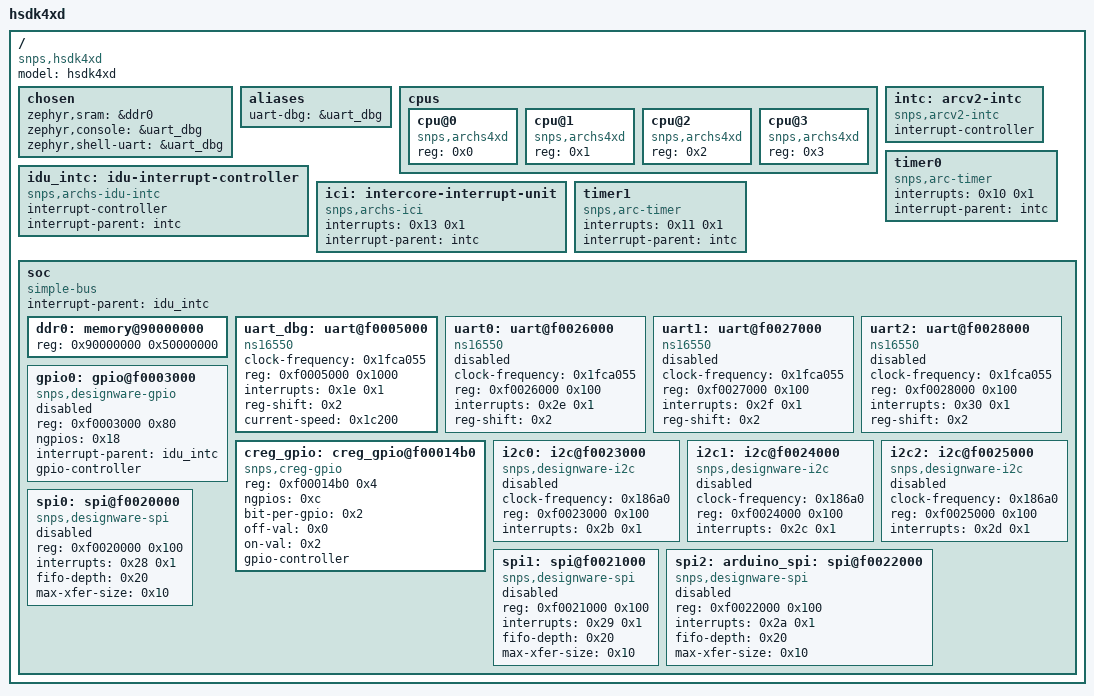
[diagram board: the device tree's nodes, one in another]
/dts-v1/;

/* node '/' defined in zephyr/dts/common/skeleton.dtsi:9 */
/ {
	#address-cells = < 0x1 >;    /* in zephyr/dts/common/skeleton.dtsi:10 */
	#size-cells = < 0x1 >;       /* in zephyr/dts/common/skeleton.dtsi:11 */
	model = "hsdk4xd";           /* in zephyr/boards/snps/hsdk4xd/hsdk4xd.dts:12 */
	compatible = "snps,hsdk4xd"; /* in zephyr/boards/snps/hsdk4xd/hsdk4xd.dts:13 */

	/* node '/chosen' defined in zephyr/dts/common/skeleton.dtsi:13 */
	chosen {
		zephyr,sram = &ddr0;           /* in zephyr/boards/snps/hsdk4xd/hsdk4xd.dts:20 */
		zephyr,console = &uart_dbg;    /* in zephyr/boards/snps/hsdk4xd/hsdk4xd.dts:21 */
		zephyr,shell-uart = &uart_dbg; /* in zephyr/boards/snps/hsdk4xd/hsdk4xd.dts:22 */
	};

	/* node '/aliases' defined in zephyr/dts/common/skeleton.dtsi:15 */
	aliases {
		uart-dbg = &uart_dbg; /* in zephyr/boards/snps/hsdk4xd/hsdk4xd.dts:16 */
	};

	/* node '/cpus' defined in zephyr/dts/arc/synopsys/arc_hs4xd.dtsi:13 */
	cpus {
		#address-cells = < 0x1 >; /* in zephyr/dts/arc/synopsys/arc_hs4xd.dtsi:14 */
		#size-cells = < 0x0 >;    /* in zephyr/dts/arc/synopsys/arc_hs4xd.dtsi:15 */

		/* node '/cpus/cpu@0' defined in zephyr/dts/arc/synopsys/arc_hs4xd.dtsi:17 */
		cpu@0 {
			device_type = "cpu";          /* in zephyr/dts/arc/synopsys/arc_hs4xd.dtsi:18 */
			compatible = "snps,archs4xd"; /* in zephyr/dts/arc/synopsys/arc_hs4xd.dtsi:19 */
			reg = < 0x0 >;                /* in zephyr/dts/arc/synopsys/arc_hs4xd.dtsi:20 */
		};

		/* node '/cpus/cpu@1' defined in zephyr/dts/arc/synopsys/arc_hs4xd.dtsi:23 */
		cpu@1 {
			device_type = "cpu";          /* in zephyr/dts/arc/synopsys/arc_hs4xd.dtsi:24 */
			compatible = "snps,archs4xd"; /* in zephyr/dts/arc/synopsys/arc_hs4xd.dtsi:25 */
			reg = < 0x1 >;                /* in zephyr/dts/arc/synopsys/arc_hs4xd.dtsi:26 */
		};

		/* node '/cpus/cpu@2' defined in zephyr/dts/arc/synopsys/arc_hs4xd.dtsi:29 */
		cpu@2 {
			device_type = "cpu";          /* in zephyr/dts/arc/synopsys/arc_hs4xd.dtsi:30 */
			compatible = "snps,archs4xd"; /* in zephyr/dts/arc/synopsys/arc_hs4xd.dtsi:31 */
			reg = < 0x2 >;                /* in zephyr/dts/arc/synopsys/arc_hs4xd.dtsi:32 */
		};

		/* node '/cpus/cpu@3' defined in zephyr/dts/arc/synopsys/arc_hs4xd.dtsi:35 */
		cpu@3 {
			device_type = "cpu";          /* in zephyr/dts/arc/synopsys/arc_hs4xd.dtsi:36 */
			compatible = "snps,archs4xd"; /* in zephyr/dts/arc/synopsys/arc_hs4xd.dtsi:37 */
			reg = < 0x3 >;                /* in zephyr/dts/arc/synopsys/arc_hs4xd.dtsi:38 */
		};
	};

	/* node '/arcv2-intc' defined in zephyr/dts/arc/synopsys/arc_hs4xd.dtsi:42 */
	intc: arcv2-intc {
		compatible = "snps,arcv2-intc"; /* in zephyr/dts/arc/synopsys/arc_hs4xd.dtsi:43 */
		interrupt-controller;           /* in zephyr/dts/arc/synopsys/arc_hs4xd.dtsi:44 */
		#interrupt-cells = < 0x2 >;     /* in zephyr/dts/arc/synopsys/arc_hs4xd.dtsi:45 */
		phandle = < 0x1 >;              /* in zephyr/dts/arc/synopsys/arc_hs4xd.dtsi:52 */
	};

	/* node '/idu-interrupt-controller' defined in zephyr/dts/arc/synopsys/arc_hs4xd.dtsi:48 */
	idu_intc: idu-interrupt-controller {
		compatible = "snps,archs-idu-intc"; /* in zephyr/dts/arc/synopsys/arc_hs4xd.dtsi:49 */
		interrupt-controller;               /* in zephyr/dts/arc/synopsys/arc_hs4xd.dtsi:50 */
		#interrupt-cells = < 0x2 >;         /* in zephyr/dts/arc/synopsys/arc_hs4xd.dtsi:51 */
		interrupt-parent = < &intc >;       /* in zephyr/dts/arc/synopsys/arc_hs4xd.dtsi:52 */
		phandle = < 0x2 >;                  /* in zephyr/dts/arc/synopsys/arc_hs4xd.dtsi:77 */
	};

	/* node '/intercore-interrupt-unit' defined in zephyr/dts/arc/synopsys/arc_hs4xd.dtsi:55 */
	ici: intercore-interrupt-unit {
		compatible = "snps,archs-ici"; /* in zephyr/dts/arc/synopsys/arc_hs4xd.dtsi:56 */
		interrupts = < 0x13 0x1 >;     /* in zephyr/dts/arc/synopsys/arc_hs4xd.dtsi:57 */
		interrupt-parent = < &intc >;  /* in zephyr/dts/arc/synopsys/arc_hs4xd.dtsi:58 */
	};

	/* node '/timer0' defined in zephyr/dts/arc/synopsys/arc_hs4xd.dtsi:61 */
	timer0: timer0 {
		compatible = "snps,arc-timer"; /* in zephyr/dts/arc/synopsys/arc_hs4xd.dtsi:62 */
		interrupts = < 0x10 0x1 >;     /* in zephyr/dts/arc/synopsys/arc_hs4xd.dtsi:63 */
		interrupt-parent = < &intc >;  /* in zephyr/dts/arc/synopsys/arc_hs4xd.dtsi:64 */
	};

	/* node '/timer1' defined in zephyr/dts/arc/synopsys/arc_hs4xd.dtsi:67 */
	timer1: timer1 {
		compatible = "snps,arc-timer"; /* in zephyr/dts/arc/synopsys/arc_hs4xd.dtsi:68 */
		interrupts = < 0x11 0x1 >;     /* in zephyr/dts/arc/synopsys/arc_hs4xd.dtsi:69 */
		interrupt-parent = < &intc >;  /* in zephyr/dts/arc/synopsys/arc_hs4xd.dtsi:70 */
	};

	/* node '/soc' defined in zephyr/dts/arc/synopsys/arc_hs4xd.dtsi:73 */
	soc {
		#address-cells = < 0x1 >;         /* in zephyr/dts/arc/synopsys/arc_hs4xd.dtsi:74 */
		#size-cells = < 0x1 >;            /* in zephyr/dts/arc/synopsys/arc_hs4xd.dtsi:75 */
		compatible = "simple-bus";        /* in zephyr/dts/arc/synopsys/arc_hs4xd.dtsi:76 */
		interrupt-parent = < &idu_intc >; /* in zephyr/dts/arc/synopsys/arc_hs4xd.dtsi:77 */
		ranges;                           /* in zephyr/dts/arc/synopsys/arc_hs4xd.dtsi:78 */

		/* node '/soc/memory@90000000' defined in zephyr/dts/arc/synopsys/arc_hs4xd.dtsi:80 */
		ddr0: memory@90000000 {
			device_type = "memory";          /* in zephyr/dts/arc/synopsys/arc_hs4xd.dtsi:81 */
			reg = < 0x90000000 0x50000000 >; /* in zephyr/dts/arc/synopsys/arc_hs4xd.dtsi:82 */
		};

		/* node '/soc/uart@f0005000' defined in zephyr/dts/arc/synopsys/arc_hs4xd.dtsi:85 */
		uart_dbg: uart@f0005000 {
			compatible = "ns16550";          /* in zephyr/dts/arc/synopsys/arc_hs4xd.dtsi:86 */
			clock-frequency = < 0x1fca055 >; /* in zephyr/dts/arc/synopsys/arc_hs4xd.dtsi:87 */
			reg = < 0xf0005000 0x1000 >;     /* in zephyr/dts/arc/synopsys/arc_hs4xd.dtsi:88 */
			interrupts = < 0x1e 0x1 >;       /* in zephyr/dts/arc/synopsys/arc_hs4xd.dtsi:89 */
			reg-shift = < 0x2 >;             /* in zephyr/dts/arc/synopsys/arc_hs4xd.dtsi:90 */
			status = "okay";                 /* in zephyr/boards/snps/hsdk4xd/hsdk4xd.dts:29 */
			current-speed = < 0x1c200 >;     /* in zephyr/boards/snps/hsdk4xd/hsdk4xd.dts:30 */
		};

		/* node '/soc/uart@f0026000' defined in zephyr/dts/arc/synopsys/arc_hs4xd.dtsi:93 */
		uart0: uart@f0026000 {
			compatible = "ns16550";          /* in zephyr/dts/arc/synopsys/arc_hs4xd.dtsi:94 */
			clock-frequency = < 0x1fca055 >; /* in zephyr/dts/arc/synopsys/arc_hs4xd.dtsi:95 */
			reg = < 0xf0026000 0x100 >;      /* in zephyr/dts/arc/synopsys/arc_hs4xd.dtsi:96 */
			interrupts = < 0x2e 0x1 >;       /* in zephyr/dts/arc/synopsys/arc_hs4xd.dtsi:97 */
			reg-shift = < 0x2 >;             /* in zephyr/dts/arc/synopsys/arc_hs4xd.dtsi:98 */
			status = "disabled";             /* in zephyr/dts/arc/synopsys/arc_hs4xd.dtsi:99 */
		};

		/* node '/soc/uart@f0027000' defined in zephyr/dts/arc/synopsys/arc_hs4xd.dtsi:102 */
		uart1: uart@f0027000 {
			compatible = "ns16550";          /* in zephyr/dts/arc/synopsys/arc_hs4xd.dtsi:103 */
			clock-frequency = < 0x1fca055 >; /* in zephyr/dts/arc/synopsys/arc_hs4xd.dtsi:104 */
			reg = < 0xf0027000 0x100 >;      /* in zephyr/dts/arc/synopsys/arc_hs4xd.dtsi:105 */
			interrupts = < 0x2f 0x1 >;       /* in zephyr/dts/arc/synopsys/arc_hs4xd.dtsi:106 */
			reg-shift = < 0x2 >;             /* in zephyr/dts/arc/synopsys/arc_hs4xd.dtsi:107 */
			status = "disabled";             /* in zephyr/dts/arc/synopsys/arc_hs4xd.dtsi:108 */
		};

		/* node '/soc/uart@f0028000' defined in zephyr/dts/arc/synopsys/arc_hs4xd.dtsi:111 */
		uart2: uart@f0028000 {
			compatible = "ns16550";          /* in zephyr/dts/arc/synopsys/arc_hs4xd.dtsi:112 */
			clock-frequency = < 0x1fca055 >; /* in zephyr/dts/arc/synopsys/arc_hs4xd.dtsi:113 */
			reg = < 0xf0028000 0x100 >;      /* in zephyr/dts/arc/synopsys/arc_hs4xd.dtsi:114 */
			interrupts = < 0x30 0x1 >;       /* in zephyr/dts/arc/synopsys/arc_hs4xd.dtsi:115 */
			reg-shift = < 0x2 >;             /* in zephyr/dts/arc/synopsys/arc_hs4xd.dtsi:116 */
			status = "disabled";             /* in zephyr/dts/arc/synopsys/arc_hs4xd.dtsi:117 */
		};

		/* node '/soc/gpio@f0003000' defined in zephyr/dts/arc/synopsys/arc_hs4xd.dtsi:120 */
		gpio0: gpio@f0003000 {
			compatible = "snps,designware-gpio"; /* in zephyr/dts/arc/synopsys/arc_hs4xd.dtsi:121 */
			reg = < 0xf0003000 0x80 >;           /* in zephyr/dts/arc/synopsys/arc_hs4xd.dtsi:122 */
			ngpios = < 0x18 >;                   /* in zephyr/dts/arc/synopsys/arc_hs4xd.dtsi:123 */
			interrupt-parent = < &idu_intc >;    /* in zephyr/dts/arc/synopsys/arc_hs4xd.dtsi:124 */
			gpio-controller;                     /* in zephyr/dts/arc/synopsys/arc_hs4xd.dtsi:126 */
			#gpio-cells = < 0x2 >;               /* in zephyr/dts/arc/synopsys/arc_hs4xd.dtsi:127 */
			status = "disabled";                 /* in zephyr/dts/arc/synopsys/arc_hs4xd.dtsi:129 */
		};

		/* node '/soc/creg_gpio@f00014b0' defined in zephyr/dts/arc/synopsys/arc_hs4xd.dtsi:132 */
		creg_gpio: creg_gpio@f00014b0 {
			compatible = "snps,creg-gpio"; /* in zephyr/dts/arc/synopsys/arc_hs4xd.dtsi:133 */
			reg = < 0xf00014b0 0x4 >;      /* in zephyr/dts/arc/synopsys/arc_hs4xd.dtsi:134 */
			ngpios = < 0xc >;              /* in zephyr/dts/arc/synopsys/arc_hs4xd.dtsi:135 */
			bit-per-gpio = < 0x2 >;        /* in zephyr/dts/arc/synopsys/arc_hs4xd.dtsi:136 */
			off-val = < 0x0 >;             /* in zephyr/dts/arc/synopsys/arc_hs4xd.dtsi:137 */
			on-val = < 0x2 >;              /* in zephyr/dts/arc/synopsys/arc_hs4xd.dtsi:138 */
			gpio-controller;               /* in zephyr/dts/arc/synopsys/arc_hs4xd.dtsi:140 */
			#gpio-cells = < 0x2 >;         /* in zephyr/dts/arc/synopsys/arc_hs4xd.dtsi:141 */
			status = "okay";               /* in zephyr/boards/snps/hsdk4xd/hsdk4xd.dts:34 */
		};

		/* node '/soc/i2c@f0023000' defined in zephyr/dts/arc/synopsys/arc_hs4xd.dtsi:146 */
		i2c0: i2c@f0023000 {
			compatible = "snps,designware-i2c"; /* in zephyr/dts/arc/synopsys/arc_hs4xd.dtsi:147 */
			clock-frequency = < 0x186a0 >;      /* in zephyr/dts/arc/synopsys/arc_hs4xd.dtsi:148 */
			#address-cells = < 0x1 >;           /* in zephyr/dts/arc/synopsys/arc_hs4xd.dtsi:149 */
			#size-cells = < 0x0 >;              /* in zephyr/dts/arc/synopsys/arc_hs4xd.dtsi:150 */
			reg = < 0xf0023000 0x100 >;         /* in zephyr/dts/arc/synopsys/arc_hs4xd.dtsi:151 */
			interrupts = < 0x2b 0x1 >;          /* in zephyr/dts/arc/synopsys/arc_hs4xd.dtsi:152 */
			status = "disabled";                /* in zephyr/dts/arc/synopsys/arc_hs4xd.dtsi:154 */
		};

		/* node '/soc/i2c@f0024000' defined in zephyr/dts/arc/synopsys/arc_hs4xd.dtsi:157 */
		i2c1: i2c@f0024000 {
			compatible = "snps,designware-i2c"; /* in zephyr/dts/arc/synopsys/arc_hs4xd.dtsi:158 */
			clock-frequency = < 0x186a0 >;      /* in zephyr/dts/arc/synopsys/arc_hs4xd.dtsi:159 */
			#address-cells = < 0x1 >;           /* in zephyr/dts/arc/synopsys/arc_hs4xd.dtsi:160 */
			#size-cells = < 0x0 >;              /* in zephyr/dts/arc/synopsys/arc_hs4xd.dtsi:161 */
			reg = < 0xf0024000 0x100 >;         /* in zephyr/dts/arc/synopsys/arc_hs4xd.dtsi:162 */
			interrupts = < 0x2c 0x1 >;          /* in zephyr/dts/arc/synopsys/arc_hs4xd.dtsi:163 */
			status = "disabled";                /* in zephyr/dts/arc/synopsys/arc_hs4xd.dtsi:165 */
		};

		/* node '/soc/i2c@f0025000' defined in zephyr/dts/arc/synopsys/arc_hs4xd.dtsi:168 */
		i2c2: i2c@f0025000 {
			compatible = "snps,designware-i2c"; /* in zephyr/dts/arc/synopsys/arc_hs4xd.dtsi:169 */
			clock-frequency = < 0x186a0 >;      /* in zephyr/dts/arc/synopsys/arc_hs4xd.dtsi:170 */
			#address-cells = < 0x1 >;           /* in zephyr/dts/arc/synopsys/arc_hs4xd.dtsi:171 */
			#size-cells = < 0x0 >;              /* in zephyr/dts/arc/synopsys/arc_hs4xd.dtsi:172 */
			reg = < 0xf0025000 0x100 >;         /* in zephyr/dts/arc/synopsys/arc_hs4xd.dtsi:173 */
			interrupts = < 0x2d 0x1 >;          /* in zephyr/dts/arc/synopsys/arc_hs4xd.dtsi:174 */
			status = "disabled";                /* in zephyr/dts/arc/synopsys/arc_hs4xd.dtsi:176 */
		};

		/* node '/soc/spi@f0020000' defined in zephyr/dts/arc/synopsys/arc_hs4xd.dtsi:179 */
		spi0: spi@f0020000 {
			compatible = "snps,designware-spi"; /* in zephyr/dts/arc/synopsys/arc_hs4xd.dtsi:180 */
			#address-cells = < 0x1 >;           /* in zephyr/dts/arc/synopsys/arc_hs4xd.dtsi:181 */
			#size-cells = < 0x0 >;              /* in zephyr/dts/arc/synopsys/arc_hs4xd.dtsi:182 */
			reg = < 0xf0020000 0x100 >;         /* in zephyr/dts/arc/synopsys/arc_hs4xd.dtsi:183 */
			interrupts = < 0x28 0x1 >;          /* in zephyr/dts/arc/synopsys/arc_hs4xd.dtsi:184 */
			fifo-depth = < 0x20 >;              /* in zephyr/dts/arc/synopsys/arc_hs4xd.dtsi:185 */
			max-xfer-size = < 0x10 >;           /* in zephyr/dts/arc/synopsys/arc_hs4xd.dtsi:186 */
			status = "disabled";                /* in zephyr/dts/arc/synopsys/arc_hs4xd.dtsi:187 */
		};

		/* node '/soc/spi@f0021000' defined in zephyr/dts/arc/synopsys/arc_hs4xd.dtsi:190 */
		spi1: spi@f0021000 {
			compatible = "snps,designware-spi"; /* in zephyr/dts/arc/synopsys/arc_hs4xd.dtsi:191 */
			#address-cells = < 0x1 >;           /* in zephyr/dts/arc/synopsys/arc_hs4xd.dtsi:192 */
			#size-cells = < 0x0 >;              /* in zephyr/dts/arc/synopsys/arc_hs4xd.dtsi:193 */
			reg = < 0xf0021000 0x100 >;         /* in zephyr/dts/arc/synopsys/arc_hs4xd.dtsi:194 */
			interrupts = < 0x29 0x1 >;          /* in zephyr/dts/arc/synopsys/arc_hs4xd.dtsi:195 */
			fifo-depth = < 0x20 >;              /* in zephyr/dts/arc/synopsys/arc_hs4xd.dtsi:196 */
			max-xfer-size = < 0x10 >;           /* in zephyr/dts/arc/synopsys/arc_hs4xd.dtsi:197 */
			status = "disabled";                /* in zephyr/dts/arc/synopsys/arc_hs4xd.dtsi:198 */
		};

		/* node '/soc/spi@f0022000' defined in zephyr/dts/arc/synopsys/arc_hs4xd.dtsi:201 */
		spi2: arduino_spi: spi@f0022000 {
			compatible = "snps,designware-spi"; /* in zephyr/dts/arc/synopsys/arc_hs4xd.dtsi:202 */
			#address-cells = < 0x1 >;           /* in zephyr/dts/arc/synopsys/arc_hs4xd.dtsi:203 */
			#size-cells = < 0x0 >;              /* in zephyr/dts/arc/synopsys/arc_hs4xd.dtsi:204 */
			reg = < 0xf0022000 0x100 >;         /* in zephyr/dts/arc/synopsys/arc_hs4xd.dtsi:205 */
			interrupts = < 0x2a 0x1 >;          /* in zephyr/dts/arc/synopsys/arc_hs4xd.dtsi:206 */
			fifo-depth = < 0x20 >;              /* in zephyr/dts/arc/synopsys/arc_hs4xd.dtsi:207 */
			max-xfer-size = < 0x10 >;           /* in zephyr/dts/arc/synopsys/arc_hs4xd.dtsi:208 */
			status = "disabled";                /* in zephyr/dts/arc/synopsys/arc_hs4xd.dtsi:209 */
		};
	};
};
